# RN8XXX_V2 register map
File version: 1.0
Registers are 32-bit, read-write, reset 0x0 unless marked. A register's access mark holds for its fields unless they carry their own. Offsets are from the block's base; [hi:lo] are bit positions; {n}, {i} and the like mark numbered series; 'fields as' and 'values as' point back to an identical list.

## GPIO
Base 0x50000000
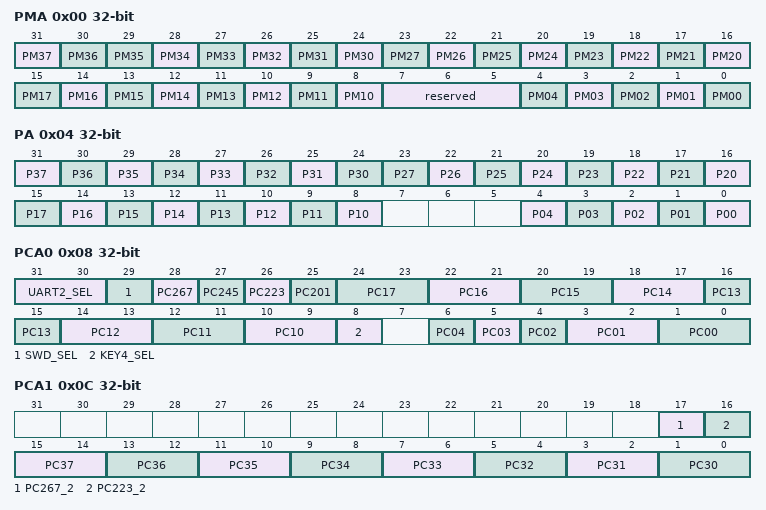
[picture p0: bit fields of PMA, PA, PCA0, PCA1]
0x00 PMA — port A mode
  [31] PM37 ro — P37 mode ,only used as input port
    0=reserved (do not use); 1=input (used as input port)
  [30] PM36 ro — P36 mode ,only used as input port
    0=reserved (do not use); 1=input (used as input port)
  [n-6] PM{n} (n=30..35) — P{n} mode
    0=output (used as output port); 1=input (used as input port)
  [n-4] PM{n} (n=20..27) — P{n} mode
    0=output (used as output port); 1=input (used as input port)
  [n-2] PM{n} (n=10..17) — P{n} mode
    0=output (used as output port); 1=input (used as input port)
  [7:5] reserved ro — do not use
  [n] PM{n:02} (n=0..4) — P{n:02} mode
    0=output (used as output port); 1=input (used as input port)
0x04 PA — port A data
  [31] P37 ro — P37 data ,always read as 1
    0=reserved (do not use); 1=high (port at high voltage)
  [30] P36 ro — P36 data ,always read as 1
    0=reserved (do not use); 1=high (port at high voltage)
  [29] P35 — P35 data
    0=low (port at low voltage); 1=high (port at high voltage)
  [28] P34 — P34 data
    0=low (port at low voltage); 1=high (port at high voltage)
  [27] P33 — P33data
    0=low (port at low voltage); 1=high (port at high voltage)
  [26] P32 — P32 data
    0=low (port at low voltage); 1=high (port at high voltage)
  [25] P31 — P31 data
    0=low (port at low voltage); 1=high (port at high voltage)
  [24] P30 — P30 data
    0=low (port at low voltage); 1=high (port at high voltage)
  [n-4] P{n} (n=20..27) — P{n} data
    0=low (port at low voltage); 1=high (port at high voltage)
  [n-2] P{n} (n=10..17) — P{n} data
    0=low (port at low voltage); 1=high (port at high voltage)
  [n] P{n:02} (n=0..4) — P{n:02} data
    0=low (port at low voltage); 1=high (port at high voltage)
0x08 PCA0 — port A mode0
  [31:30] UART2_SEL — UART2 PAD selection
    0=PC245 (P24 and P25 used as UART2 PAD when PC245=1); 1=PC001 (P00 and P01 used as UART2 PAD); 2=PC223 (P22 and P23 used as UART2 PAD when PC223_2=1); 3=PC267 (P26 and P27 used as UART2 PAD when PC267_2=1)
  [29] SWD_SEL — SWD selection
    0=IO (P24 and P25 used as general IO); 1=SWD (P24 and P25 used as SWD IO)
  [28] PC267 — P26 and P27 mode
    0=IO (used as general IO); 1=UART3 (used as UART3 IO)
  [27] PC245 — P24 and P25 mode
    0=IO (used as general IO); 1=UART2 (used as UAR2 IO)
  [26] PC223 — P22 and P23 mode
    0=IO (used as general IO); 1=UART1 (used as UART1 IO)
  [25] PC201 — P20 and P21 mode
    0=IO (used as general IO); 1=UART0 (used as UART0 IO)
  [2n-10:2n-11] PC{n} (n=10..17) — P{n} mode
    0=IO (used as general IO); 1=KEY (used as KEY input); 2=TC_OUT (used as TC output); 3=TC_IN (used as TC input)
  [8] KEY4_SEL — P04 key4 mode
    0=PC04 (set P04 mode by PC04 bit); 1=KEY4 (P04 as KEY4)
  [6] PC04 — P04 mode
    0=IO (used as general IO); 1=ANALOG_IN (used as analog input)
  [5] PC03 — P03 mode
    values as PC04
  [4] PC02 — P02 mode
    values as PC04
  [3:2] PC01 — P01 mode
    0=IO (used as general IO); 1=ANALOG_IN (used as analog input); 2=KEY3 (used key3); 3=TX2 (used as uart2 tx)
  [1:0] PC00 — P00 mode
    0=IO (used as general IO); 1=ANALOG_IN (used as analog input); 2=KEY2 (used key2); 3=RX2 (used as uart2 rx)
0x0C PCA1 — port A mode1
  [17] PC267_2 — P267 mode
    0=P267 (P26 and P27 determined by P267 PCA0.bit28); 1=UART2 (P26 as RX2 and P27 as TX2)
  [16] PC223_2 — P223 mode
    0=P223 (P22 and P23 determined by P223 PCA0.bit26); 1=UART2 (P22 as RX2 and P23 as TX2)
  [15:14] PC37 — P37 mode
    0=IO (used as general IO); 1=EXT_INT7 (used as external interrupt request NO.7); 2=POSCI (used as POSC input); 3=POSCI (used as POSC input)
  [13:12] PC36 — P36 mode
    0=IO (used as general IO); 1=EXT_INT6 (used as external interrupt request NO.6); 2=POSCO (used as POSC output); 3=POSCO (used as POSC output)
  [11:10] PC35 — P35 mode
    0=IO (used as general IO); 1=EXT_INT5 (used as external interupt request No.5); 2=TC_IN (used as TC input); 3=CF2 (used as D2F CF2)
  [9:8] PC34 — P34 mode
    0=IO (used as general IO); 1=EXT_INT4 (used as external interupt request No.4); 2=SF_OUT (used as CF/SF_OUT); 3=CF1 (used as D2F CF1)
  [7:6] PC33 — P33 mode
    0=IO (used as general IO); 1=EXT_INT3 (used as external interupt request No.3); 2=TC_IN (used as TC input); 3=CF0 (used as D2F CF0)
  [5:4] PC32 — P32 mode
    0=IO (used as general IO); 1=EXT_INT2 (used as external interupt request No.2); 2=RTC_OUT (used as RTC pulse output); 3=KEY5 (used as KEY5)
  [3:2] PC31 — P31 mode
    0=IO (used as general IO); 1=EXT_INT1 (used as external interupt request No.1); 2=TC_IN (used as TC input); 3=RX4 (used as RX4)
  [1:0] PC30 — P30 mode
    0=IO (used as general IO); 1=EXT_INT0 (used as external interupt request No.0); 2=TC_IN (used as TC input); 3=TX4 (used as TX4)
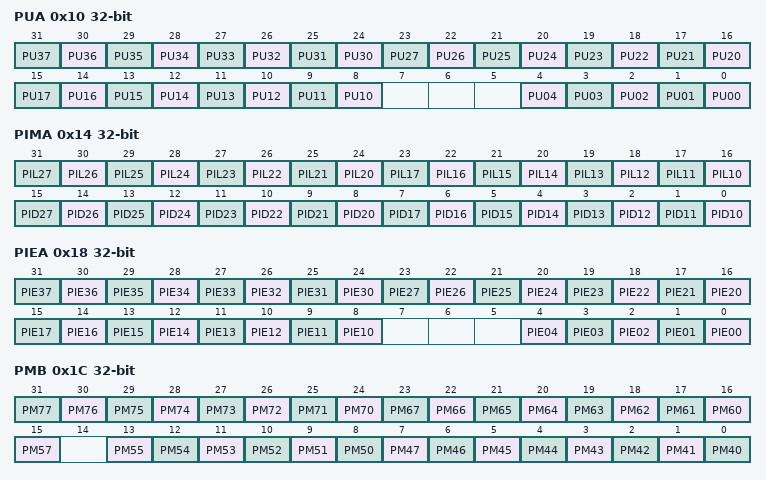
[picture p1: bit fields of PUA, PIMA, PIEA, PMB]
0x10 PUA — port A pull-up config
  [all] fields
    0=no (do not pull-up); 1=yes (pull-up)
  [n-6] PU{n} (n=30..37) — P{n} pull-up config
  [n-4] PU{n} (n=20..27) — P{n} pull-up config
  [n-2] PU{n} (n=10..17) — P{n} pull-up config
  [n] PU{n:02} (n=0..4) — P{n:02} pull-up config
0x14 PIMA — port A input config
  [n+4] PIL{n} (n=20..27) — P{n} input config
    0=CMOS (use CMOS input buffer); 1=TTL (use TTL input buffer)
  [n+6] PIL{n} (n=10..17) — P{n} input config
    0=CMOS (use CMOS input buffer); 1=TTL (use TTL input buffer)
  [n-12] PID{n} (n=20..27) — P{n} output config
    0=normal output; 1=N_OPEN_DRAIN (N channel open drain output)
  [n-10] PID{n} (n=10..17) — P{n} output config
    values as PID20
0x18 PIEA — port A input enable
  [all] fields
    0=enable (used as input); 1=disable (do not use as input)
  [n-6] PIE{n} (n=30..37) — input enable
  [n-4] PIE{n} (n=20..27) — input enable
  [n-2] PIE{n} (n=10..17) — input enable
  [n] PIE{n:02} (n=0..4) — input enable
0x1C PMB — port B mode
  [all] fields
    0=output (used as output); 1=input (used as input)
  [n-46] PM{n} (n=70..77) — port mode
  [n-44] PM{n} (n=60..67) — port mode
  [15] PM57 — port mode
  [n-42] PM{n} (n=50..55) — port mode
  [n-40] PM{n} (n=40..47) — port mode
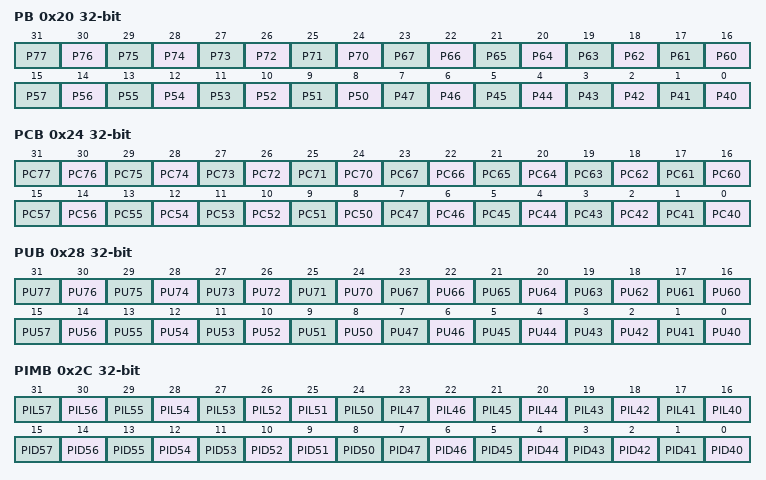
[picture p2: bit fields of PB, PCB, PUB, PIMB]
0x20 PB — port B data
  [all] fields
    0=low (low voltage detected); 1=pending (high voltage detected)
  [n-46] P{n} (n=70..77) — port voltage
  [n-44] P{n} (n=60..67) — port voltage
  [n-42] P{n} (n=50..57) — port voltage
  [n-40] P{n} (n=40..47) — port voltage
0x24 PCB — port B selection
  [all] fields
    0=IO (used as general IO); 1=SPEC (used as special IO)
  [n-46] PC{n} (n=70..77) — port selection
  [n-44] PC{n} (n=60..67) — port selection
  [n-42] PC{n} (n=50..57) — port selection
  [n-40] PC{n} (n=40..47) — port selection
0x28 PUB — port B pull-up enable
  [n-46] PU{n} (n=70..77) — port pull-down enable
    0=no (do not pull-down); 1=yes (pull-down)
  [n-44] PU{n} (n=60..67) — port pull-down enable
    0=no (do not pull-down); 1=yes (pull-down)
  [n-42] PU{n} (n=50..57) — port pull-up enable
    0=no (do not pull-up); 1=yes (pull-up)
  [n-40] PU{n} (n=40..47) — port pull-up enable
    0=no (do not pull-up); 1=yes (pull-up)
0x2C PIMB — port B input mode
  [n-26] PIL{n} (n=52..57) — port input mode
    0=CMOS (used as CMOS input); 1=TTL (used as TTL input)
  [25] PIL51 — port input mode
    0=CMOS (used as CMOS input); 1=reserved (do not use)
  [24] PIL50 — port input mode
    0=CMOS (used as CMOS input); 1=reserved (do not use)
  [n-24] PIL{n} (n=40..47) — port input mode
    0=CMOS (used as CMOS input); 1=TTL (used as TTL input)
  [n-42] PID{n} (n=52..57) — port output mode
    0=normal; 1=N_OPEN_DRAIN (N channel open drain output)
  [9] PID51 — port output mode
    0=normal; 1=reserved (do not use)
  [8] PID50 — port output mode
    0=normal; 1=reserved (do not use)
  [n-40] PID{n} (n=40..47) — port output mode
    0=normal; 1=N_OPEN_DRAIN (N channel open drain output)
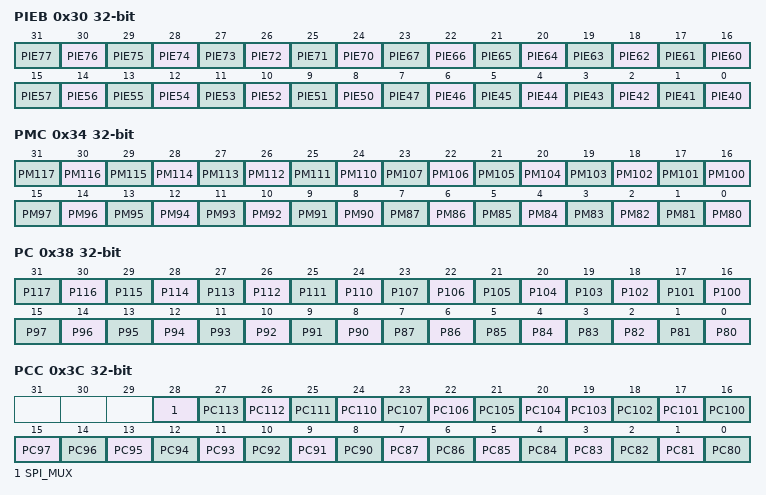
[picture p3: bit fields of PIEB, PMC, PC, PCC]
0x30 PIEB — port B input enable
  [all] fields
    0=enable (used as input); 1=disable (do not used as input)
  [n-46] PIE{n} (n=70..77) — input enable
  [n-44] PIE{n} (n=60..67) — input enable
  [n-42] PIE{n} (n=50..57) — input enable
  [n-40] PIE{n} (n=40..47) — input enable
0x34 PMC — port C mode
  [all] fields
    0=output (used as output); 1=input (used as input)
  [n-86] PM{n} (n=110..117) — port mode
  [n-84] PM{n} (n=100..107) — port mode
  [n-82] PM{n} (n=90..97) — port mode
  [n-80] PM{n} (n=80..87) — port mode
0x38 PC — port C data
  [all] fields
    0=low (low voltage on port); 1=high voltage on port
  [n-86] P{n} (n=110..117) — port data
  [n-84] P{n} (n=100..107) — port data
  [n-82] P{n} (n=90..97) — port data
  [n-80] P{n} (n=80..87) — port data
0x3C PCC — PC port mode
  [28] SPI_MUX — port mode
    0=P46_P51 (used P46 P47 P50 P51 as SPI0); 1=P110_P113 (used P110~P113 as SPI0)
  [27] PC113 — port mode
    0=IO (used as general IO); 1=SPI0_MOSI (used as SPI0_MOSI)
  [26] PC112 — port mode
    0=IO (used as general IO); 1=SPI0_MISO (used as SPI0_MISO)
  [25] PC111 — port mode
    0=IO (used as general IO); 1=SPI0_SCLK (used as SPI0_SCLK)
  [24] PC110 — port mode
    0=IO (used as general IO); 1=SPI0_SCSN (used as SPI0_SCSN)
  [23] PC107 — port mode
    0=IO (used as general IO); 1=SPI3_MOSI (used as SPI3_MOSI)
  [22] PC106 — port mode
    0=IO (used as general IO); 1=SPI3_MISO (used as SPI3_MISO)
  [21] PC105 — port mode
    0=IO (used as general IO); 1=SPI3_SCLK (used as SPI3_SCLK)
  [20] PC104 — port mode
    0=IO (used as general IO); 1=SPI3_SCSN (used as SPI3_SCSN)
  [n-84] PC{n} (n=100..103) — port mode
    0=IO (used as general IO); 1=LCD (used as LCD IO)
  [n-82] PC{n} (n=90..97) — port mode
    0=IO (used as general IO); 1=LCD (used as LCD IO)
  [n-80] PC{n} (n=80..87) — port mode
    0=IO (used as general IO); 1=LCD (used as LCD IO)
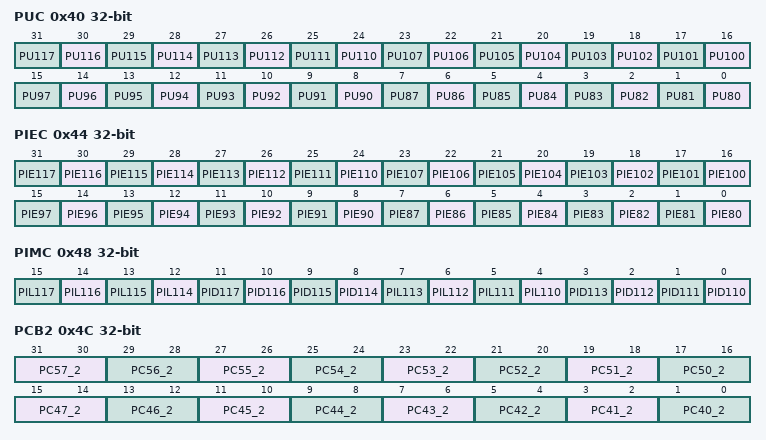
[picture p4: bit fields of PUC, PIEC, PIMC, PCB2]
0x40 PUC — port C pull-down selection
  [n-86] PU{n} (n=110..117) — port pull-up enable
    0=no (do not pull-up); 1=yes (pull-up)
  [n-84] PU{n} (n=100..107) — port pull-up enable
    0=no (do not pull-up); 1=yes (pull-up)
  [n-82] PU{n} (n=90..97) — port pull-down enable
    0=no (do not pull-down); 1=yes (pull-down)
  [n-80] PU{n} (n=80..87) — port pull-down enable
    0=no (do not pull-down); 1=yes (pull-down)
0x44 PIEC — PC port input enable
  [all] fields
    0=enable (used as input); 1=disable (do not used as input)
  [n-86] PIE{n} (n=110..117) — port input enable
  [n-84] PIE{n} (n=100..107) — port input enable
  [n-82] PIE{n} (n=90..97) — port input enable
  [n-80] PIE{n} (n=80..87) — port input enable
0x48 PIMC — port C input mode
  [n-102] PIL{n} (n=114..117) — port input mode
    0=CMOS (used as CMOS input); 1=TTL (used as TTL input)
  [n-106] PID{n} (n=114..117) — port output mode
    0=normal; 1=N_OPEN_DRAIN (N channel open drain output)
  [n-106] PIL{n} (n=110..113) — port input mode
    0=CMOS (used as CMOS input); 1=TTL (used as TTL input)
  [n-110] PID{n} (n=110..113) — port output mode
    0=normal; 1=N_OPEN_DRAIN (N channel open drain output)
0x4C PCB2 — port B selection2
  [31:30] PC57_2 — port selection
    0=PC53 (used PC53 selection); 1=TCIN (used as TCIN); 2=TC1_P[1] (used as TC1_P[1]); 3=reserved3 (do not use)
  [29:28] PC56_2 — port selection
    0=PC56 (used PC56 selection); 1=TCIN (used as TCIN); 2=TC1_N[1] (used as TC1_N[1]); 3=reserved3 (do not use)
  [27:26] PC55_2 — port selection
    0=PC55 (used PC55 selection); 1=TCIN (used as TCIN); 2=TC1_P[0] (used as TC1_P[0]); 3=SPI1_MOSI (used as SPI1_MOSI)
  [25:24] PC54_2 — port selection
    0=PC54 (used PC54 selection); 1=TCIN (used as TCIN); 2=TC1_N[0] (used as TC1_N[0]); 3=SPI1_MISO (used as SPI1_MISO)
  [23:22] PC53_2 — port selection
    0=PC53 (used PC53 selection); 1=TCIN (used as TCIN); 2=TC0_P[1] (used as TC0_P[1]); 3=SPI1_SCLK (used as SPI1_SCLK)
  [21:20] PC52_2 — port selection
    0=PC52 (used PC52 selection); 1=TCIN (used as TCIN); 2=TC0_N[1] (used as TC0_N[1]); 3=SPI1_SCSN (used as SPI1_SCSN)
  [19:18] PC51_2 — port selection
    0=PC51 (used PC51 selection); 1=RTCOUT (used as RTCOUT); 2=SPI0_SCLK (used as SPI0_SCLK); 3=SF2 (used as SF2(INT7 out))
  [17:16] PC50_2 — port selection
    0=PC50 (used PC50 selection); 1=RTCOUT (used as RTCOUT); 2=SPI0_SCSN (used as SPI0_SCSN); 3=SF1 (used as SF1(INT6 out))
  [15:14] PC47_2 — port selection
    0=PC47 (used PC47 selection); 1=TX4 (used as TX4); 2=CF0 (used as CF0); 3=CF1 (used as CF1)
  [13:12] PC46_2 — port selection
    0=PC46 (used PC46 selection); 1=RX4 (used as RX4); 2=CF1 (used as CF1); 3=CF2 (used as CF1)
  [11:10] PC45_2 — port selection
    0=PC45 (used PC45 selection); 1=KEY7 (used as KEY7); 2=reserved (do not use)
  [9:8] PC44_2 — port selection
    0=PC44 (used PC44 selection); 1=KEY6 (used as KEY6); 2=reserved (do not use)
  [7:6] PC43_2 — port selection
    0=PC43 (used PC43 selection); 1=INT5 (used as INT5); 2=SPI1_MOSI (used as SPI1_MOSI); 3=SPI2_MOSI (used as SPI2_MOSI)
  [5:4] PC42_2 — port selection
    0=PC42 (used PC42 selection); 1=INT4 (used as INT4); 2=SPI1_MISO (used as SPI1_MISO); 3=SPI2_MISO (used as SPI2_MISO)
  [3:2] PC41_2 — port selection
    0=PC41 (used PC41 selection); 1=INT3 (used as INT3); 2=SPI1_SCLK (used as SPI1_SCLK); 3=SPI2_SCLK (used as SPI2_SCLK)
  [1:0] PC40_2 — port selection
    0=PC40 (used PC40 selection); 1=INT1 (used as INT1); 2=SPI1_SCSN (used as SPI1_SCSN); 3=SPI2_SCSN (used as SPI2_SCSN)
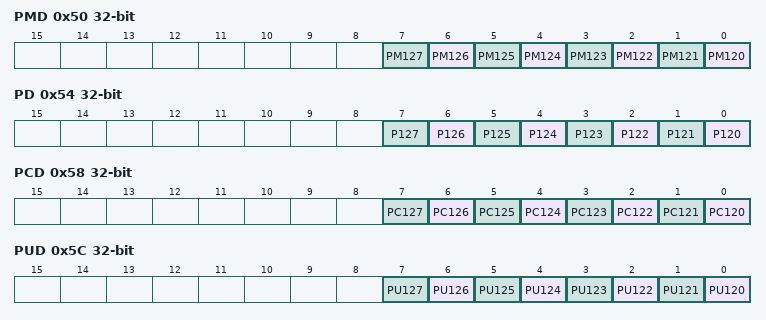
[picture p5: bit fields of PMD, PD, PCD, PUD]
0x50 PMD — port D mode
  [all] fields
    0=output (used as output); 1=input (used as input)
  [n-120] PM{n} (n=120..127) — port mode
0x54 PD — port D data
  [all] fields
    0=low (low voltage on port); 1=high voltage on port
  [n-120] P{n} (n=120..127) — port data
0x58 PCD — PD port mode
  [all] fields
    0=IO (used as general IO); 1=LCD (used as LCD IO)
  [n-120] PC{n} (n=120..127) — port mode
0x5C PUD — port D pull-down selection
  [all] fields
    0=no (do not pull-down); 1=yes (pull-down)
  [n-120] PU{n} (n=120..127) — port pull-down enable
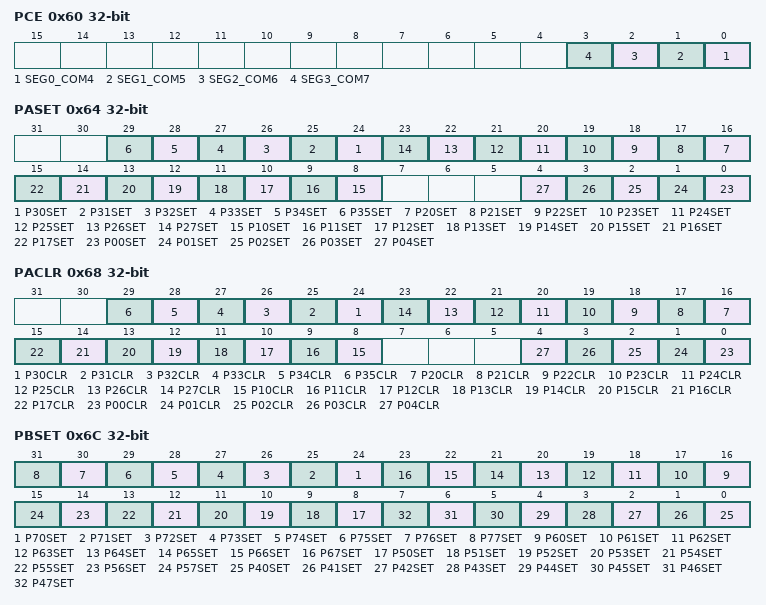
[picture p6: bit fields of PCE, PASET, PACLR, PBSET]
0x60 PCE — SEGCOM mode selection
  [all] fields
    0=SEG (used as SEG); 1=COM (used as COM)
  [n] SEG{n}_COM{n+4} (n=0..3) — SEG{n}_COM{n+4} mode selection
0x64 PASET — PA SET BIT register
  [all] fields
    0=no effect; 1=set as 1
  [n-6] P{n}SET (n=30..35) — P{n} SET 1
  [n-4] P{n}SET (n=20..27) — P{n} SET 1
  [n-2] P{n}SET (n=10..17) — P{n} SET 1
  [n] P{n:02}SET (n=0..4) — P{n:02} SET 1
0x68 PACLR — P CLEAR BIT register
  [all] fields
    0=no effect; 1=set as 0
  [n-6] P{n}CLR (n=30..35) — P{n} CLR 0
  [n-4] P{n}CLR (n=20..27) — P{n} CLR 0
  [n-2] P{n}CLR (n=10..17) — P{n} CLR 0
  [n] P{n:02}CLR (n=0..4) — P{n:02} CLR 0
0x6C PBSET — PB SET BIT register
  [all] fields
    0=no effect; 1=set as 1
  [n-46] P{n}SET (n=70..77) — P{n} SET 1
  [n-44] P{n}SET (n=60..67) — P{n} SET 1
  [n-42] P{n}SET (n=50..57) — P{n} SET 1
  [n-40] P{n}SET (n=40..47) — P{n} SET 1
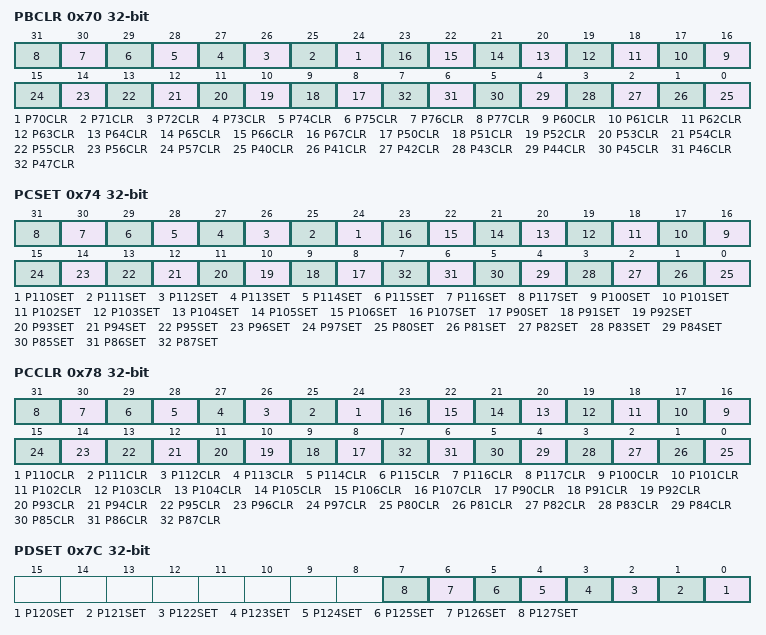
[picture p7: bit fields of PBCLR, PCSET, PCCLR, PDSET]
0x70 PBCLR — PB CLR BIT register
  [all] fields
    0=no effect; 1=set as 0
  [n-46] P{n}CLR (n=70..77) — P{n} CLR 0
  [n-44] P{n}CLR (n=60..67) — P{n} CLR 0
  [n-42] P{n}CLR (n=50..57) — P{n} CLR 0
  [n-40] P{n}CLR (n=40..47) — P{n} CLR 0
0x74 PCSET — PC SET BIT register
  [all] fields
    0=no effect; 1=set as 1
  [n-86] P{n}SET (n=110..117) — P{n} SET 1
  [n-84] P{n}SET (n=100..107) — P{n} SET 1
  [n-82] P{n}SET (n=90..97) — P{n} SET 1
  [n-80] P{n}SET (n=80..87) — P{n} SET 1
0x78 PCCLR — PC CLR BIT register
  [all] fields
    0=no effect; 1=set as 0
  [n-86] P{n}CLR (n=110..117) — P{n} CLR 0
  [n-84] P{n}CLR (n=100..107) — P{n} CLR 0
  [n-82] P{n}CLR (n=90..97) — P{n} CLR 0
  [n-80] P{n}CLR (n=80..87) — P{n} CLR 0
0x7C PDSET — PD SET BIT register
  [all] fields
    0=no effect; 1=set as 1
  [n-120] P{n}SET (n=120..127) — P{n} SET 1
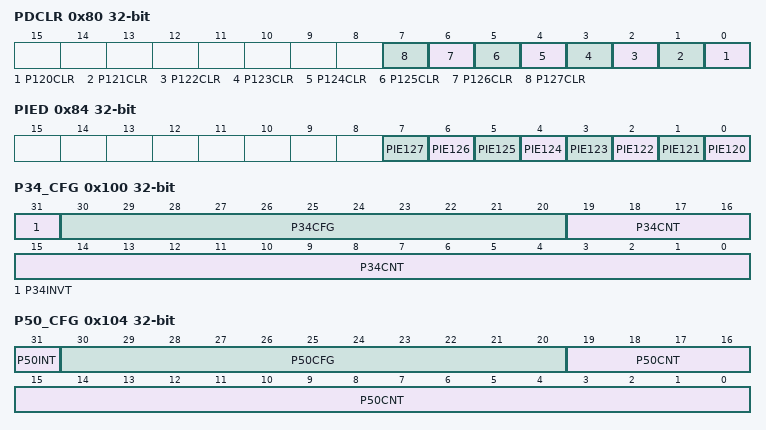
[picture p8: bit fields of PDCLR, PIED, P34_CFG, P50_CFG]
0x80 PDCLR — PD CLR BIT register
  [all] fields
    0=no effect; 1=set as 0
  [n-120] P{n}CLR (n=120..127) — P{n} CLR 0
0x84 PIED — PD port input enable
  [all] fields
    0=enable (used as input); 1=disable (do not used as input)
  [n-120] PIE{n} (n=120..127) — port input enable
0x88 PIMD — port D input mode
0x100 P34_CFG — P34 pulse counter register
  [31] P34INVT — P34 level invert config, after divider
    0=no effect; 1=invert level
  [30:20] P34CFG — P34 pulse input div config,div=P34CFG+1, range:0~2048
  [19:0] P34CNT ro — P34 pulse input counter, clear after read
0x104 P50_CFG — P50 pulse counter register
  [31] P50INT — P50 level invert config, after divider
    0=no effect; 1=invert level
  [30:20] P50CFG — P50 pulse input div config,div=P50CFG+1, range:0~2048
  [19:0] P50CNT ro — P50 pulse input counter, clear after read
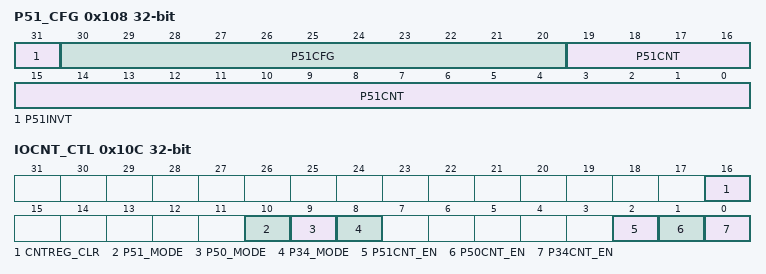
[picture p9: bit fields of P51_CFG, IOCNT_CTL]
0x108 P51_CFG — P51 pulse counter register
  [31] P51INVT — P51 level invert config, after divider
    0=no effect; 1=invert level
  [30:20] P51CFG — P51 pulse input div config,div=P51CFG+1, range:0~2048
  [19:0] P51CNT ro — P51 pulse input counter, clear after read
0x10C IOCNT_CTL — IO pulse counter register
  [16] CNTREG_CLR — IOCNT clear mode config register
    0=clr_mode (clear after read); 1=sum mode, not clear
  [10] P51_MODE — P51 mode config register
    0=rising (counter start at rising edge); 1=falling (counter start at falling edge)
  [9] P50_MODE — P50 mode config register
    values as P51_MODE
  [8] P34_MODE — P34 trigger mode config register
    values as P51_MODE
  [2] P51CNT_EN — P51 counter mode enable
    0=disable IOCNT; 1=enable IOCNT
  [1] P50CNT_EN — P50 counter mode enable
    0=disable IOCNT; 1=enable IOCNT
  [0] P34CNT_EN — P34 counter mode enable
    0=disable IOCNT; 1=enable IOCNT
